# IOC register map
Vendor: Texas Instruments
Peripheral module from a debugger description file (folder CC27xxx10).
Registers are 32-bit, access per field, reset 0x0 unless marked. A register's access mark holds for its fields unless they carry their own. Offsets are as the file gives them; lines under a group give offsets from that group; [hi:lo] are bit positions; {n}, {i} and the like mark numbered series; 'fields as' and 'values as' point back to an identical list; <NAME> marks a mode.

## IOC — IO Controller
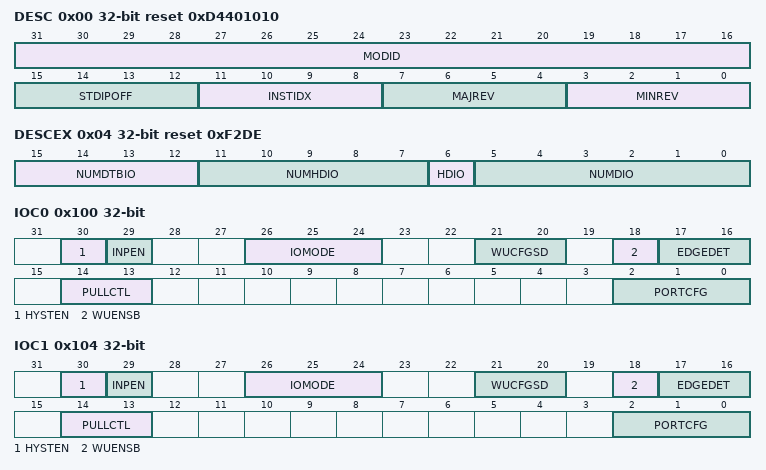
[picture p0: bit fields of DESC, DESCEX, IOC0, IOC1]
0x00 DESC rw reset 0xD4401010 — Description Register. This register provides IP module ID, revision information, instance index and standard MMR registers offset.
  [31:16] MODID — Module identifier used to uniquely identify this IP.
  [15:12] STDIPOFF — Standard IP MMR block offset. Standard IP MMRs are the set of from aggregated IRQ registers till DTB. 0: Standard IP MMRs do not exist 0x1-0xF: Standard IP MMRs begin at offset of (64*STDIPOFF from the base IP address)
  [11:8] INSTIDX — IP Instance ID number. If multiple instances of IP exist in the device, this field can identify the instance number (0-15).
  [7:4] MAJREV — Major revision of IP (0-15).
  [3:0] MINREV — Minor revision of IP (0-15).
0x04 DESCEX reset 0xF2DE — Extended Description Register. This register provides configuration details of the IP to software drivers and end users.
  [15:12] NUMDTBIO rw — Number of DTB IOs supported. Total DTB IOs supported is NUMDTBIO value +1.
    15=MAXIMUM (Highest possible value); 0=MINIMUM (Smallest value)
  [11:7] NUMHDIO rw — Number of high drive IOs supported. Total high drive IOs supported is NUMHDIO value +1.
    31=MAXIMUM (Highest possible value); 0=MINIMUM (Smallest value)
  [6] HDIO rw — High drive IO supported by IOC.
    1=PRESENT (HD IO supported by IOC); 0=ABSENT (HD IO not supported by IOC)
  [5:0] NUMDIO rw — Number of DIOs supported. Total DIOs supported is NUMDIO value +1.
    63=MAXIMUM (Highest possible value); 0=MINIMUM (Smallest value)
0x100 IOC0 — Configuration of DIO0
  [30] HYSTEN rw — This field controls input hysteresis
    1=EN (Input hysteresis enabled); 0=DIS (Input hysteresis disabled)
  [29] INPEN rw — This field controls the input capability of DIO
    1=EN (Input enabled); 0=DIS (Input disabled)
  [26:24] IOMODE rw — IO Mode. Setting this to value 0x6 or 0x7 will default to normal IO behavior.
    5=OPENS_INV (Open Source, inverted IO); 4=OPENS (Open Source, normal IO); 3=OPEND_INV (Open Drain, inverted IO); 2=OPEND (Open Drain, normal IO); 1=INVERTED (Inverted IO); 0=NORMAL (Normal IO)
  [21:20] WUCFGSD rw — Wakeup configuration from shutdown
    3=WAKE_HIGH (Wakeup triggered when pad level is high); 2=WAKE_LOW (Wakeup triggered when pad level is low); 1=DIS_1 (Wakeup disabled); 0=DIS_0 (Wakeup disabled)
  [18] WUENSB rw — Wakeup enable from standby
    1=EN (Wakeup enabled (effective only if EDGEDET is enabled)); 0=DIS (Wakeup disabled)
  [17:16] EDGEDET rw — Edge detect configuration
    3=EDGE_BOTH (Positive and negative edge detection); 2=EDGE_POS (Positive edge detection); 1=EDGE_NEG (Negative edge detection); 0=EDGE_DIS (No edge detection)
  [14:13] PULLCTL rw — Pull control. Setting this to value 0x3 disables pull.
    2=PULL_UP (Pull up enabled); 1=PULL_DOWN (Pull down enabled); 0=PULL_DIS (No pull)
  [2:0] PORTCFG rw — Selects usage of DIO0
    7=DTB (Digital Test Bus function); 6=ANA (Analog function); {v}=PFUNC{v} (Digital peripheral function-{v}) (v=1..5); 0=BASE (Base function)
0x104 IOC1 — Configuration of DIO1
  [30] HYSTEN rw — This field controls input hysteresis
    values as IOC0.HYSTEN
  [29] INPEN rw — This field controls the input capability of DIO
    1=EN (Input enabled); 0=DIS (Input disabled)
  [26:24] IOMODE rw — IO Mode. Setting this to value 0x6 or 0x7 will default to normal IO behavior.
    values as IOC0.IOMODE
  [21:20] WUCFGSD rw — Wakeup configuration from shutdown
    values as IOC0.WUCFGSD
  [18] WUENSB rw — Wakeup enable from standby
    values as IOC0.WUENSB
  [17:16] EDGEDET rw — Edge detect configuration
    values as IOC0.EDGEDET
  [14:13] PULLCTL rw — Pull control. Setting this to value 0x3 disables pull.
    values as IOC0.PULLCTL
  [2:0] PORTCFG rw — Selects usage of DIO1
    values as IOC0.PORTCFG
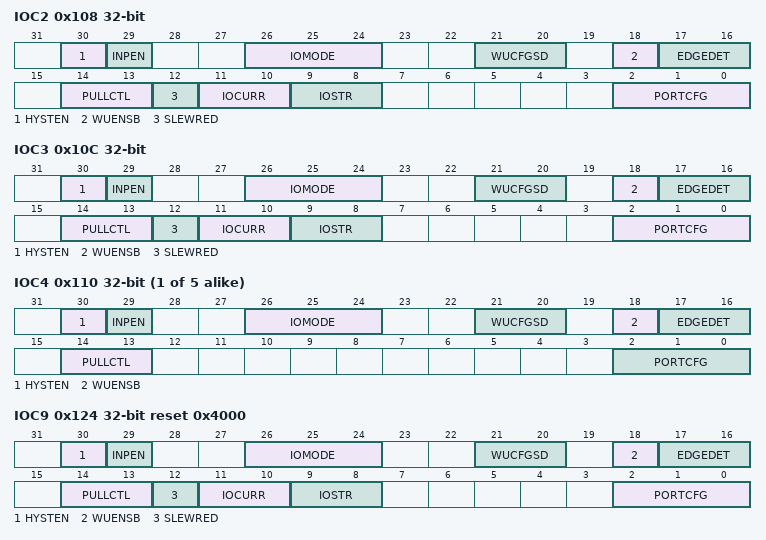
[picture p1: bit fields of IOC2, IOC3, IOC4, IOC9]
0x108 IOC2 — Configuration of DIO2
  [30] HYSTEN rw — This field controls input hysteresis
    values as IOC0.HYSTEN
  [29] INPEN rw — This field controls the input capability of DIO
    1=EN (Input enabled); 0=DIS (Input disabled)
  [26:24] IOMODE rw — IO Mode. Setting this to value 0x6 or 0x7 will default to normal IO behavior.
    values as IOC0.IOMODE
  [21:20] WUCFGSD rw — Wakeup configuration from shutdown
    values as IOC0.WUCFGSD
  [18] WUENSB rw — Wakeup enable from standby
    values as IOC0.WUENSB
  [17:16] EDGEDET rw — Edge detect configuration
    values as IOC0.EDGEDET
  [14:13] PULLCTL rw — Pull control. Setting this to value 0x3 disables pull.
    values as IOC0.PULLCTL
  [12] SLEWRED rw — Slew rate configuration
    1=REDUCED (Reduced slew rate); 0=NORMAL (Normal slew rate)
  [11:10] IOCURR rw — Output current configuration. Writing value 0x3 defaults to 2mA current setting.
    2=CUR_8MA (8mA); 1=CUR_4MA (4mA); 0=CUR_2MA (2mA)
  [9:8] IOSTR rw — Drive strength configuration
    3=MAX (Maximum drive strength); 2=MEDIUM (Medium drive strength); 1=MIN (Minimum drive stregnth); 0=AUTO (Automatic drive strength adjustment)
  [2:0] PORTCFG rw — Selects usage of DIO2
    values as IOC0.PORTCFG
0x10C IOC3 — Configuration of DIO3
  [30] HYSTEN rw — This field controls input hysteresis
    values as IOC0.HYSTEN
  [29] INPEN rw — This field controls the input capability of DIO
    1=EN (Input enabled); 0=DIS (Input disabled)
  [26:24] IOMODE rw — IO Mode. Setting this to value 0x6 or 0x7 will default to normal IO behavior.
    values as IOC0.IOMODE
  [21:20] WUCFGSD rw — Wakeup configuration from shutdown
    values as IOC0.WUCFGSD
  [18] WUENSB rw — Wakeup enable from standby
    values as IOC0.WUENSB
  [17:16] EDGEDET rw — Edge detect configuration
    values as IOC0.EDGEDET
  [14:13] PULLCTL rw — Pull control. Setting this to value 0x3 disables pull.
    values as IOC0.PULLCTL
  [12] SLEWRED rw — Slew rate configuration
    1=REDUCED (Reduced slew rate); 0=NORMAL (Normal slew rate)
  [11:10] IOCURR rw — Output current configuration. Writing value 0x3 defaults to 2mA current setting.
    2=CUR_8MA (8mA); 1=CUR_4MA (4mA); 0=CUR_2MA (2mA)
  [9:8] IOSTR rw — Drive strength configuration
    values as IOC2.IOSTR
  [2:0] PORTCFG rw — Selects usage of DIO3
    values as IOC0.PORTCFG
{0x100+4i} IOC{i} (i=4..8) — Configuration of DIO{i}
  [30] HYSTEN rw — This field controls input hysteresis
    values as IOC0.HYSTEN
  [29] INPEN rw — This field controls the input capability of DIO
    1=EN (Input enabled); 0=DIS (Input disabled)
  [26:24] IOMODE rw — IO Mode. Setting this to value 0x6 or 0x7 will default to normal IO behavior.
    values as IOC0.IOMODE
  [21:20] WUCFGSD rw — Wakeup configuration from shutdown
    values as IOC0.WUCFGSD
  [18] WUENSB rw — Wakeup enable from standby
    values as IOC0.WUENSB
  [17:16] EDGEDET rw — Edge detect configuration
    values as IOC0.EDGEDET
  [14:13] PULLCTL rw — Pull control. Setting this to value 0x3 disables pull.
    values as IOC0.PULLCTL
  [2:0] PORTCFG rw — Selects usage of DIO{i}
    values as IOC0.PORTCFG
0x124 IOC9 reset 0x4000 — Configuration of DIO9
  [30] HYSTEN rw — This field controls input hysteresis
    values as IOC0.HYSTEN
  [29] INPEN rw — This field controls the input capability of DIO
    1=EN (Input enabled); 0=DIS (Input disabled)
  [26:24] IOMODE rw — IO Mode. Setting this to value 0x6 or 0x7 will default to normal IO behavior.
    values as IOC0.IOMODE
  [21:20] WUCFGSD rw — Wakeup configuration from shutdown
    values as IOC0.WUCFGSD
  [18] WUENSB rw — Wakeup enable from standby
    values as IOC0.WUENSB
  [17:16] EDGEDET rw — Edge detect configuration
    values as IOC0.EDGEDET
  [14:13] PULLCTL rw — Pull control. Setting this to value 0x3 disables pull.
    values as IOC0.PULLCTL
  [12] SLEWRED rw — Slew rate configuration
    1=REDUCED (Reduced slew rate); 0=NORMAL (Normal slew rate)
  [11:10] IOCURR rw — Output current configuration. Writing value 0x3 defaults to 2mA current setting.
    2=CUR_8MA (8mA); 1=CUR_4MA (4mA); 0=CUR_2MA (2mA)
  [9:8] IOSTR rw — Drive strength configuration
    values as IOC2.IOSTR
  [2:0] PORTCFG rw — Selects usage of DIO9
    values as IOC0.PORTCFG
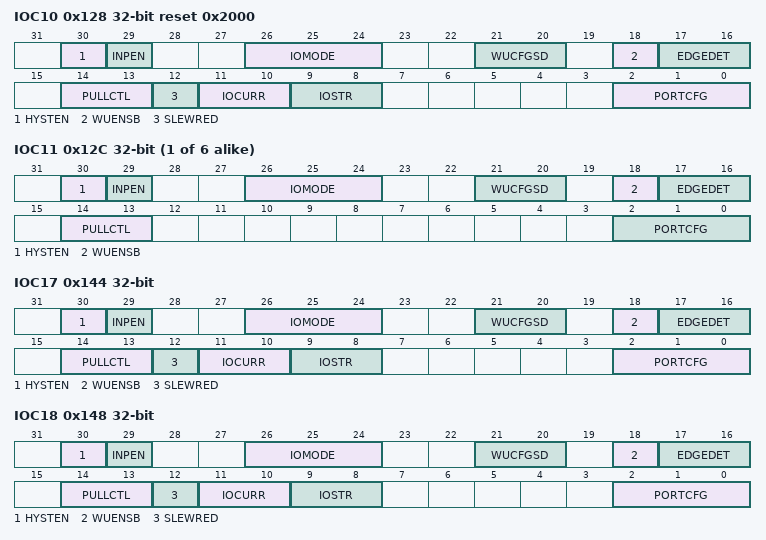
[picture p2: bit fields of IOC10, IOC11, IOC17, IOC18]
0x128 IOC10 reset 0x2000 — Configuration of DIO10
  [30] HYSTEN rw — This field controls input hysteresis
    values as IOC0.HYSTEN
  [29] INPEN rw — This field controls the input capability of DIO
    1=EN (Input enabled); 0=DIS (Input disabled)
  [26:24] IOMODE rw — IO Mode. Setting this to value 0x6 or 0x7 will default to normal IO behavior.
    values as IOC0.IOMODE
  [21:20] WUCFGSD rw — Wakeup configuration from shutdown
    values as IOC0.WUCFGSD
  [18] WUENSB rw — Wakeup enable from standby
    values as IOC0.WUENSB
  [17:16] EDGEDET rw — Edge detect configuration
    values as IOC0.EDGEDET
  [14:13] PULLCTL rw — Pull control. Setting this to value 0x3 disables pull.
    values as IOC0.PULLCTL
  [12] SLEWRED rw — Slew rate configuration
    1=REDUCED (Reduced slew rate); 0=NORMAL (Normal slew rate)
  [11:10] IOCURR rw — Output current configuration. Writing value 0x3 defaults to 2mA current setting.
    2=CUR_8MA (8mA); 1=CUR_4MA (4mA); 0=CUR_2MA (2mA)
  [9:8] IOSTR rw — Drive strength configuration
    values as IOC2.IOSTR
  [2:0] PORTCFG rw — Selects usage of DIO10
    values as IOC0.PORTCFG
{0x100+4i} IOC{i} (i=11..16) — Configuration of DIO{i}
  fields as IOC4
0x144 IOC17 — Configuration of DIO17
  [30] HYSTEN rw — This field controls input hysteresis
    values as IOC0.HYSTEN
  [29] INPEN rw — This field controls the input capability of DIO
    1=EN (Input enabled); 0=DIS (Input disabled)
  [26:24] IOMODE rw — IO Mode. Setting this to value 0x6 or 0x7 will default to normal IO behavior.
    values as IOC0.IOMODE
  [21:20] WUCFGSD rw — Wakeup configuration from shutdown
    values as IOC0.WUCFGSD
  [18] WUENSB rw — Wakeup enable from standby
    values as IOC0.WUENSB
  [17:16] EDGEDET rw — Edge detect configuration
    values as IOC0.EDGEDET
  [14:13] PULLCTL rw — Pull control. Setting this to value 0x3 disables pull.
    values as IOC0.PULLCTL
  [12] SLEWRED rw — Slew rate configuration
    1=REDUCED (Reduced slew rate); 0=NORMAL (Normal slew rate)
  [11:10] IOCURR rw — Output current configuration. Writing value 0x3 defaults to 2mA current setting.
    2=CUR_8MA (8mA); 1=CUR_4MA (4mA); 0=CUR_2MA (2mA)
  [9:8] IOSTR rw — Drive strength configuration
    values as IOC2.IOSTR
  [2:0] PORTCFG rw — Selects usage of DIO17
    values as IOC0.PORTCFG
0x148 IOC18 — Configuration of DIO18
  [30] HYSTEN rw — This field controls input hysteresis
    values as IOC0.HYSTEN
  [29] INPEN rw — This field controls the input capability of DIO
    1=EN (Input enabled); 0=DIS (Input disabled)
  [26:24] IOMODE rw — IO Mode. Setting this to value 0x6 or 0x7 will default to normal IO behavior.
    values as IOC0.IOMODE
  [21:20] WUCFGSD rw — Wakeup configuration from shutdown
    values as IOC0.WUCFGSD
  [18] WUENSB rw — Wakeup enable from standby
    values as IOC0.WUENSB
  [17:16] EDGEDET rw — Edge detect configuration
    values as IOC0.EDGEDET
  [14:13] PULLCTL rw — Pull control. Setting this to value 0x3 disables pull.
    values as IOC0.PULLCTL
  [12] SLEWRED rw — Slew rate configuration
    1=REDUCED (Reduced slew rate); 0=NORMAL (Normal slew rate)
  [11:10] IOCURR rw — Output current configuration. Writing value 0x3 defaults to 2mA current setting.
    2=CUR_8MA (8mA); 1=CUR_4MA (4mA); 0=CUR_2MA (2mA)
  [9:8] IOSTR rw — Drive strength configuration
    values as IOC2.IOSTR
  [2:0] PORTCFG rw — Selects usage of DIO18
    values as IOC0.PORTCFG
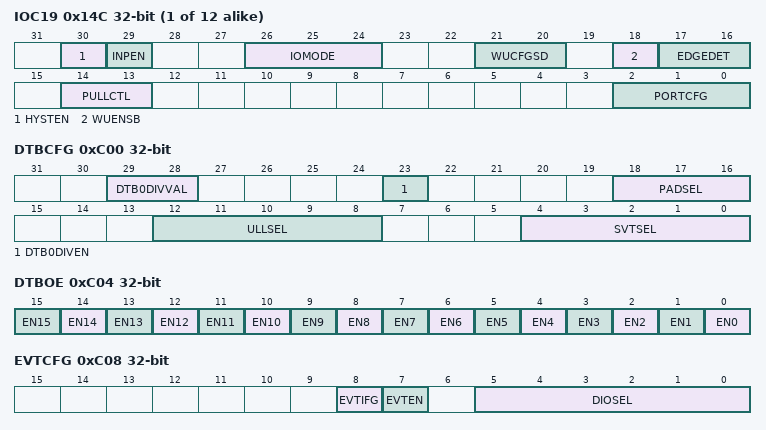
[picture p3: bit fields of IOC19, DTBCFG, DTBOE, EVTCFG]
{0x100+4i} IOC{i} (i=19..30) — Configuration of DIO{i}
  fields as IOC4
0xC00 DTBCFG — DTB configuration
  [29:28] DTB0DIVVAL rw — These bits are used to configure the DTB[0] divider value.
    3=DIVBY16 (Divide by 16); 2=DIVBY8 (Divide by 8); 1=DIVBY4 (Divide by 4); 0=DIVBY2 (Divide by 2)
  [23] DTB0DIVEN rw — This bit is used to enable the programmable divider on DTB[0].
    1=EN (Enable); 0=DIS (Disable)
  [18:16] PADSEL rw — Selects which 3 DTB lines out of total 16 are routed to DTB pins 15 to 13.
    5=DTB2TO0 (DTB[2:0] selected); 4=DTB5TO3 (DTB[5:3] selected); 3=DTB8TO6 (DTB[8:6] selected); 2=DTB11TO9 (DTB[11:9] selected); 1=DTB14TO12 (DTB[14:12] selected); 0=DTB15TO13 (DTB[15:13] selected)
  [12:8] ULLSEL rw — ULL DTB Mux selection
    9=SYS0 (SYS0 IP); 8=DEBUGSS (Debug subsystem IP); 7=PMUDIG (PMU digital IP); 6=IOC (IO controller IP); 5=RTC (RTC IP); 4=PMU (PMUDLC IP); 3=PMCTL (PM controller IP); 2=EVTULL (ULL Event IP); 1=CKMDIG (CKMDIG IP); 0=SVTIP (SVT IPs)
  [4:0] SVTSEL rw — SVT DTB Mux selection
    18=VIMS (VIMS IP); 17=UART1 (Instance 1 of UART IP); 16=UART0 (Instance 0 of UART IP); 15=SYSTIMER (System timer IP); 14=EVTSVT (SVT Event IP); 13=SRAM (SRAM IP); 12=SPI (SPI IP); 11=NVMNW (FLASH(NVM) IP); 10=LRFBLEDIG (LRF IP); 9=LGPT (LGPT IP); 8=AES (AES IP); 7=I2C (I2C IP); 6=GPIO (GPIO IP); 5=DMA (DMA IP); 4=CPUSS (CPU subsystem IP); 3=CLKCTRL (Clock controller IP); 2=BUS (BUS IP); 1=ADC (ADC IP); 0=DIS (Disable)
0xC04 DTBOE — DTB output enable
  [all] fields
    1=EN (DTB output enabled); 0=DIS (DTB output disabled)
  [n] EN{n} rw (n=0..15) — Enables DTB output {n}
0xC08 EVTCFG — Event configuration. This register is used to select DIO for IOC to publish event on ULL event fabric. It also contains enable bit that is used to mask the event and event flag bit.
  [8] EVTIFG rw — Event flag. It is set when edge is detected on selected DIO. Note: The edge detector flop is cleared for the selected DIO when EVTIFG is cleared by software.
    1=SET (Set ULL event); 0=CLR (Clear ULL event)
  [7] EVTEN rw — Enables IOC to publish event on AON event fabric when EVTIFG is set.
    1=EN (Enable); 0=DIS (Disable)
  [5:0] DIOSEL rw — This is used to select DIO for event generation. For example, DIOSEL = 0x0 selects DIO0 and DIOSEL = 0x8 selects DIO8.
0xC0C TEST
  [0] SEL rw — This is used to drive SWDIO output data and output enable from debug sub-system onto TBD (TDO) pad.
    1=HI (Output data and output enable driven based on debug sub-system inputs); 0=LO (Output data and output enable managed by IOC)
0xC10 DTBSTAT ro — DTB status register. This register captures the value of DTBL3 mux layer output.
  [15:0] VAL — This bit field captures the final 16-bit value of DTB signals provided from IOC to DTB device pins.
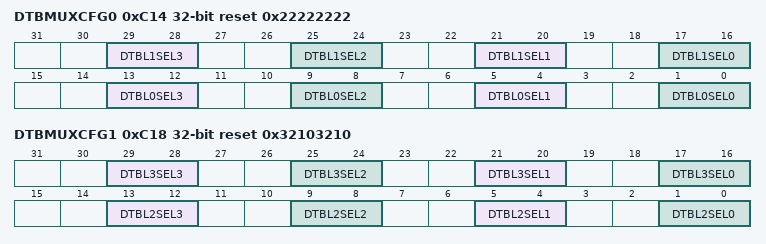
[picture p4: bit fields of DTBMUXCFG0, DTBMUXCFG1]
0xC14 DTBMUXCFG0 reset 0x22222222 — DTB mux configuration 0 register. This register is used to configure DTB level 0 and level 1 mux layers.
  [29:28] DTBL1SEL3 rw — Select bits for DTBL1 fourth mux
    3=RESERVED (Defaults to selection of DTB[15:12]); 2=Selects DTB[15:12]; 1=Selects CKMD DTB[15:12]; 0=Selects PMCTL DTB[15:12]
  [25:24] DTBL1SEL2 rw — Select bits for DTBL1 third mux
    3=RESERVED (Defaults to selection of DTB[11:8]); 2=Selects DTB[11:8]; 1=Selects CKMD DTB[11:8]; 0=Selects PMCTL DTB[11:8]
  [21:20] DTBL1SEL1 rw — Select bits for DTBL1 second mux
    3=RESERVED (Defaults to selection of DTB[7:4]); 2=Selects DTB[7:4]; 1=Selects CKMD DTB[7:4]; 0=Selects PMCTL DTB[7:4]
  [17:16] DTBL1SEL0 rw — Select bits for DTBL1 first mux
    3=RESERVED (Defaults to selection of DTB[3:0]); 2=Selects DTB[3:0]; 1=Selects CKMD DTB[3:0]; 0=Selects PMCTL DTB[3:0]
  [13:12] DTBL0SEL3 rw — Select bits for DTBL0 fourth mux
    values as DTBL1SEL3
  [9:8] DTBL0SEL2 rw — Select bits for DTBL0 third mux
    values as DTBL1SEL2
  [5:4] DTBL0SEL1 rw — Select bits for DTBL0 second mux
    values as DTBL1SEL1
  [1:0] DTBL0SEL0 rw — Select bits for DTBL0 first mux
    values as DTBL1SEL0
0xC18 DTBMUXCFG1 reset 0x32103210 — DTB mux configuration 1 register. This register is used to configure DTB level 2 and level 3 mux layers.
  [29:28] DTBL3SEL3 rw — Select bits for DTBL3 fourth mux
    3=Selects DTBL2 fourth mux output; 2=Selects DTBL2 third mux output; 1=Selects DTBL2 second mux output; 0=Selects DTBL2 first mux output
  [25:24] DTBL3SEL2 rw — Select bits for DTBL3 third mux
    values as DTBL3SEL3
  [21:20] DTBL3SEL1 rw — Select bits for DTBL3 second mux
    values as DTBL3SEL3
  [17:16] DTBL3SEL0 rw — Select bits for DTBL3 first mux
    values as DTBL3SEL3
  [13:12] DTBL2SEL3 rw — Select bits for DTBL2 fourth mux
    3=Selects DTBL1 fourth mux output; 2=Selects DTBL1 third mux output; 1=Selects DTBL1 second mux output; 0=Selects DTBL1 first mux output
  [9:8] DTBL2SEL2 rw — Select bits for DTBL2 third mux
    3=Selects DTBL0 fourth mux output; 2=Selects DTBL0 third mux output; 1=Selects DTBL0 second mux output; 0=Selects DTBL0 first mux output
  [5:4] DTBL2SEL1 rw — Select bits for DTBL2 second mux
    3=Selects DTB[15:12]; 2=Selects DTB[11:8]; 1=Selects DTB[7:4]; 0=Selects DTB[3:0]
  [1:0] DTBL2SEL0 rw — Select bits for DTBL2 first mux
    values as DTBL2SEL1
